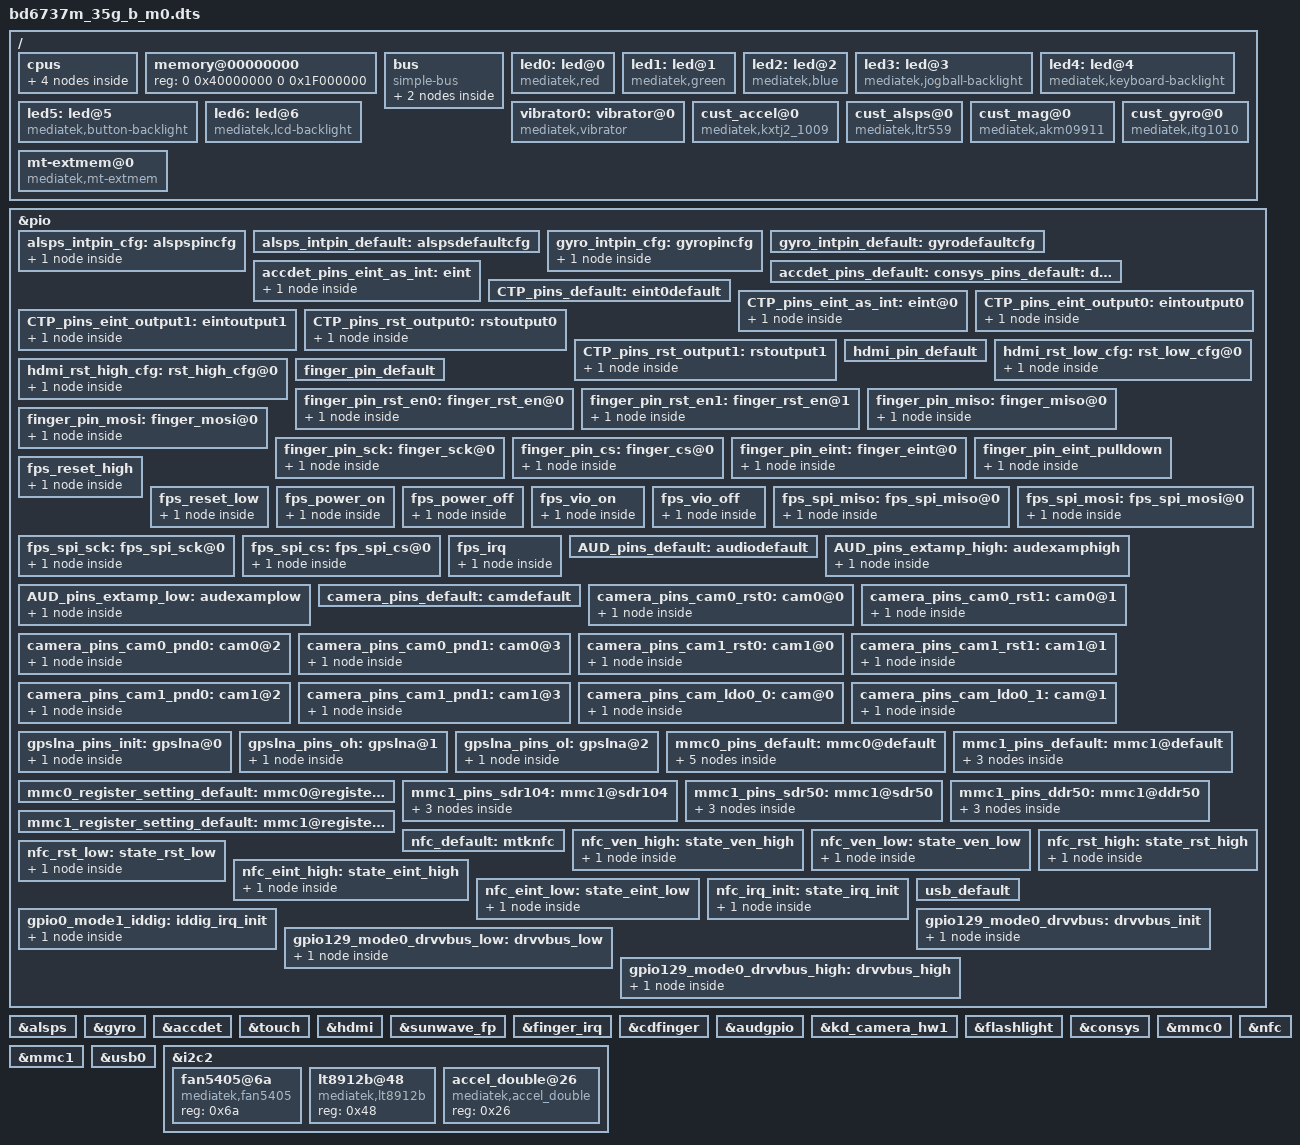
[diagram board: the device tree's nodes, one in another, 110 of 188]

/dts-v1/;

#include "mt6735m.dtsi"

/ {
	cpus {
		#address-cells = <1>;
		#size-cells = <0>;
/*		enable-method = "mediatek,mt6735-smp"; */

		cpu0: cpu@000 {
			device_type = "cpu";
			compatible = "arm,cortex-a53";
			reg = <0x000>;
			enable-method = "spin-table";
			cpu-release-addr = <0x0 0x40000200>;
			clock-frequency = <1100000000>;
		};

		cpu1: cpu@001 {
			device_type = "cpu";
			compatible = "arm,cortex-a53";
			reg = <0x001>;
			enable-method = "spin-table";
			cpu-release-addr = <0x0 0x40000200>;
			clock-frequency = <1100000000>;
		};

		cpu2: cpu@002 {
			device_type = "cpu";
			compatible = "arm,cortex-a53";
			reg = <0x002>;
			enable-method = "spin-table";
			cpu-release-addr = <0x0 0x40000200>;
			clock-frequency = <1100000000>;
		};

		cpu3: cpu@003 {
			device_type = "cpu";
			compatible = "arm,cortex-a53";
			reg = <0x003>;
			enable-method = "spin-table";
			cpu-release-addr = <0x0 0x40000200>;
			clock-frequency = <1100000000>;
		};
	};

	memory@00000000 {
		device_type = "memory";
		reg = <0 0x40000000 0 0x1F000000>;
	};

	bus {
		compatible = "simple-bus";
		#address-cells = <1>;
		#size-cells = <1>;
		ranges = <0 0 0 0xffffffff>;

		MALI@0x13040000 {
			compatible = "arm,malit720", "arm,mali-t72x", "arm,malit7xx", "arm,mali-midgard";
			reg = <0x13040000 0x4000>;
			interrupts = <0 212 0x8>, <0 211 0x8>, <0 210 0x8>;
			interrupt-names = "JOB", "MMU", "GPU";
			clock-frequency = <550000000>;
		};

		MTKFB@5e200000 {
			compatible = "mediatek,MTKFB";
			reg = <0x7F000000 0x1000000>;
		};

	};
	led0:led@0 {
		compatible = "mediatek,red";
		led_mode = <0>;
		data = <1>;
		pwm_config = <0 0 0 0 0>;
	};
	led1:led@1 {
		compatible = "mediatek,green";
		led_mode = <0>;
		data = <1>;
		pwm_config = <0 0 0 0 0>;
	};
	led2:led@2 {
		compatible = "mediatek,blue";
		led_mode = <0>;
		data = <1>;
		pwm_config = <0 0 0 0 0>;
	};
	led3:led@3 {
		compatible = "mediatek,jogball-backlight";
		led_mode = <0>;
		data = <1>;
		pwm_config = <0 0 0 0 0>;
	};
	led4:led@4 {
		compatible = "mediatek,keyboard-backlight";
		led_mode = <0>;
		data = <1>;
		pwm_config = <0 0 0 0 0>;
	};
	led5:led@5 {
		compatible = "mediatek,button-backlight";
		led_mode = <0>;
		data = <1>;
		pwm_config = <0 0 0 0 0>;
	};
	led6:led@6 {
		compatible = "mediatek,lcd-backlight";
		led_mode = <5>;
		data = <1>;
		pwm_config = <0 0 0 0 0>;
	};
	vibrator0:vibrator@0 {
		compatible = "mediatek,vibrator";
		vib_timer = <25>;
		vib_limit = <9>;
		vib_vol= <5>;
	};
 /* sensor standardization */
		cust_accel@0 {
		compatible = "mediatek,kxtj2_1009";
		i2c_num	= <2>;
		i2c_addr = <0x0e 0 0 0>;
		direction = <6>;
		power_id = <0xffff>;
		power_vol = <0>;
		firlen = <16>;
		is_batch_supported = <0>;
		};

		cust_alsps@0 {
		compatible				= "mediatek,ltr559";
		i2c_num					= <2>;
		i2c_addr				= <0x23 0 0 0>;
		polling_mode_ps			= <0>;
		polling_mode_als		= <1>;
		power_id				= <0xffff>;
		power_vol				= <0>;
/* Total has 15 level*/
	    //als_level	= <50 100 200 500 4000 8000 12000 16000 20000 24000 28000 32000 36000 40000 65535>;
/*  Total has 16 range*/
  		//als_value	= <0 15 32 80 625 1250 1875 2500 3125 3750 4375 5000 5625 6250 10240 10240>;
   als_level	= <25 50  75 100 200 500 1000 2000 5000 10000 20000 28000  36000 40000 65535>;
   als_value	= <0 300 500 700 1100 2005 3058 5005 8008 10010 12000 16000 20000 20000 20000 20000>;

		ps_threshold_high		=  <120>;
		ps_threshold_low		=  <80>;
		is_batch_supported_ps	= <0>;
		is_batch_supported_als	= <0>;
		};

		cust_mag@0 {
		compatible				= "mediatek,akm09911";
		i2c_num					= <2>;
		i2c_addr				= <0x0D 0 0 0>;
		direction				= <1>;
		power_id				= <0xffff>;
		power_vol				= <0>;
		is_batch_supported			= <0>;
		};

		cust_gyro@0 {
		compatible				= "mediatek,itg1010";
		i2c_num					= <2>;
		i2c_addr				= <0x68 0 0 0>;
		direction				= <3>;
		power_id				= <0xffff>;
		power_vol				= <0>;
		firlen					= <0>;
		is_batch_supported			= <0>;
		};

	mt-extmem@0 {
		compatible = "mediatek,mt-extmem";
	};
};
/* sensor gpio standization */
&pio {
	alsps_intpin_cfg: alspspincfg {

	    pins_cmd_dat {
			pins = <PINMUX_GPIO100__FUNC_GPIO100>;
			slew-rate = <0>;
			bias-pull-up = <00>;
		};
	};

	alsps_intpin_default: alspsdefaultcfg {

	};

	gyro_intpin_cfg: gyropincfg {

	    pins_cmd_dat {
			pins = <PINMUX_GPIO64__FUNC_GPIO64>;
			slew-rate = <0>;
			bias-pull-down = <00>;
		};
	};

	gyro_intpin_default: gyrodefaultcfg {

	};
};
&alsps {
	pinctrl-names = "pin_default", "pin_cfg";
	pinctrl-0 = <&alsps_intpin_default>;
	pinctrl-1 = <&alsps_intpin_cfg>;
	status = "okay";

};

&gyro {
	pinctrl-names = "pin_default", "pin_cfg";
	pinctrl-0 = <&gyro_intpin_default>;
	pinctrl-1 = <&gyro_intpin_cfg>;
	status = "okay";

};
/* sensor end */
&accdet {
		accdet-mic-vol = <7>;
		headset-mode-setting = <0x500 0x200 1 0x1F0 0x800 0x800 0x20>;
		accdet-plugout-debounce = <20>;
		/*1:ACC mode, 2:low cost without in bias, 6:low cost with in bias*/
		accdet-mic-mode = <1>;
		/*0--MD_MAX--UP_MAX--DW_MAX*/
		headset-three-key-threshold = <0 80 220 500>;
		/*0--MD_MAX--VOICE_MAX--UP_MAX--DW_MAX*/
		headset-four-key-threshold = <0 58 121 192 450>;
		
		pinctrl-names = "default", "state_eint_as_int";
		pinctrl-0 = <&accdet_pins_default>;
		pinctrl-1 = <&accdet_pins_eint_as_int>;
		status = "okay";
};
&pio {
	accdet_pins_default:default {
	};
	accdet_pins_eint_as_int:eint{
		pins_cmd_dat {
			pins = <PINMUX_GPIO83__FUNC_GPIO83>;
			slew-rate = <0>;
			bias-pull-up = <11>;
			output-high;
		};
	};
};
&touch {
	tpd-resolution = <720 1280>;
	use-tpd-button = <1>;
	tpd-key-num = <3>;
	tpd-key-local= <139 172 158 0>;
	tpd-key-dim-local = <100 1500 80 65 250 1500 80 65 400 1500 80 65 0 0 0 0>;
	tpd-max-touch-num = <5>;
	tpd-filter-enable = <1>;
	tpd-filter-pixel-density = <124>;
	tpd-filter-custom-prameters = <0 0 0 0 0 0 0 0 0 0 0 0>;
	tpd-filter-custom-speed = <0 0 0>;
	pinctrl-names = "default", "state_eint_as_int", "state_eint_output0", "state_eint_output1",
		"state_rst_output0", "state_rst_output1";
	pinctrl-0 = <&CTP_pins_default>;
	pinctrl-1 = <&CTP_pins_eint_as_int>;
	pinctrl-2 = <&CTP_pins_eint_output0>;
	pinctrl-3 = <&CTP_pins_eint_output1>;
	pinctrl-4 = <&CTP_pins_rst_output0>;
	pinctrl-5 = <&CTP_pins_rst_output1>;
	status = "okay";
};
&pio {
	CTP_pins_default: eint0default {
	};
	CTP_pins_eint_as_int: eint@0 {
		pins_cmd_dat {
			pins = <PINMUX_GPIO10__FUNC_GPIO10>;
			slew-rate = <0>;
			bias-pull-up = <00>;
		};
	};
	CTP_pins_eint_output0: eintoutput0 {
		pins_cmd_dat {
			pins = <PINMUX_GPIO10__FUNC_GPIO10>;
			slew-rate = <1>;
			output-low;
		};
	};
	CTP_pins_eint_output1: eintoutput1 {
		pins_cmd_dat {
			pins = <PINMUX_GPIO10__FUNC_GPIO10>;
			slew-rate = <1>;
			output-high;
		};
	};
	CTP_pins_rst_output0: rstoutput0 {
		pins_cmd_dat {
			pins = <PINMUX_GPIO62__FUNC_GPIO62>;
			slew-rate = <1>;
			output-low;
		};
	};
	CTP_pins_rst_output1: rstoutput1 {
		pins_cmd_dat {
			pins = <PINMUX_GPIO62__FUNC_GPIO62>;
			slew-rate = <1>;
			output-high;
		};
	};
};
/* TOUCH end */
/************** zhou IR_RECEIVER start **************/
//#define IR_RECEIVER_EINT_PIN_NUM    123
//#define IR_RECEIVER_EINT_PIN        PINMUX_GPIO123__FUNC_GPIO123

//&ir_irq{
//		interrupt-parent = <&eintc>;
//		interrupts = <IR_RECEIVER_EINT_PIN_NUM IRQ_TYPE_LEVEL_LOW>;
//		debounce = <IR_RECEIVER_EINT_PIN_NUM 200>;
//		status = "okay";
//	};	
	
/************** zhou hdmi start **************/	
/*
&mhl{
   pinctrl-names = "default",	
                   "i2s_dat_def","i2s_dat_cfg","i2s_ws_def","i2s_ws_cfg","i2s_ck_def","i2s_ck_cfg",
                   "rst_low_cfg", "rst_high_cfg";

   pinctrl-0 = <&hdmi_pin_default>;
   pinctrl-1 = <&hdmi_i2s_dat_def>;
   pinctrl-2 = <&hdmi_i2s_dat_cfg>;
   pinctrl-3 = <&hdmi_i2s_ws_def>;
   pinctrl-4 = <&hdmi_i2s_ws_cfg>;   
   pinctrl-5 = <&hdmi_i2s_ck_def>;
   pinctrl-6 = <&hdmi_i2s_ck_cfg>;   
   pinctrl-7 = <&hdmi_rst_low_cfg>;
   pinctrl-8 = <&hdmi_rst_high_cfg>;      
  	status = "okay";  
};

&pio {
	hdmi_pin_default:hdmi_pin_default{
	 
  };
	hdmi_i2s_dat_def:i2s_dat_def@0{
		  pins_cmd_dat {
			pins = <PINMUX_GPIO78__FUNC_GPIO78>;
			slew-rate = <0>;
			bias-pull-down = <11>;
		};
	 };  
	hdmi_i2s_dat_cfg:i2s_dat_cfg@0{
		  pins_cmd_dat {
			pins = <PINMUX_GPIO78__FUNC_I2S3_DO>;
			slew-rate = <1>;
		};
	 };    
	hdmi_i2s_ws_def:i2s_ws_def@0{
		  pins_cmd_dat {
			pins = <PINMUX_GPIO79__FUNC_GPIO79>;
			slew-rate = <0>;
			bias-pull-down = <11>;
		};
	 };  
	hdmi_i2s_ws_cfg:i2s_ws_cfg@0{
		  pins_cmd_dat {
			pins = <PINMUX_GPIO79__FUNC_I2S3_LRCK>;
			slew-rate = <1>;
		};
	 };
	hdmi_i2s_ck_def:i2s_ck_def@0{
		  pins_cmd_dat {
			pins = <PINMUX_GPIO80__FUNC_GPIO80>;
			slew-rate = <0>;
			bias-pull-down = <11>;
		};
	 };  
	hdmi_i2s_ck_cfg:i2s_ck_cfg@0{
		  pins_cmd_dat {
			pins = <PINMUX_GPIO80__FUNC_I2S3_BCK>;
			slew-rate = <1>;
		};
	 };	   
	 hdmi_rst_low_cfg:rst_low_cfg@0{
	     pins_cmd_dat {
		   pins = <PINMUX_GPIO120__FUNC_GPIO120>;
		   slew-rate=<1>;
		   output-low;
		 };
	 };
	 hdmi_rst_high_cfg:rst_high_cfg@0{
	     pins_cmd_dat {
		   pins = <PINMUX_GPIO120__FUNC_GPIO120>;
		   slew-rate=<1>;
		   output-high;
		 };
	 };
};
*/

&hdmi{
   pinctrl-names = "default", "rst_low_cfg", "rst_high_cfg";

   pinctrl-0 = <&hdmi_pin_default>;  
   pinctrl-1 = <&hdmi_rst_low_cfg>;
   pinctrl-2 = <&hdmi_rst_high_cfg>;      
  	status = "okay";  
};

&pio {
	hdmi_pin_default:hdmi_pin_default{
	 
  };   
	 hdmi_rst_low_cfg:rst_low_cfg@0{
	     pins_cmd_dat {
		   pins = <PINMUX_GPIO120__FUNC_GPIO120>;
		   slew-rate=<1>;
		   output-low;
		 };
	 };
	 hdmi_rst_high_cfg:rst_high_cfg@0{
	     pins_cmd_dat {
		   pins = <PINMUX_GPIO120__FUNC_GPIO120>;
		   slew-rate=<1>;
		   output-high;
		 };
	 };
};

/************** zhou FINGERPRINT start **************/
/*SUNWAVE FINGERPRINT DTS begin*/
#define SUNWAVE_FINGER_EINT_PIN_NUM    125
#define SUNWAVE_FINGER_EINT_PIN        PINMUX_GPIO125__FUNC_GPIO125
#define SUNWAVE_FINGER_RST_PIN         PINMUX_GPIO127__FUNC_GPIO127

&sunwave_fp{
    pinctrl-names = "default","finger_rst_en0","finger_rst_en1","finger_miso","finger_mosi","finger_sck","finger_cs","finger_eint","finger_eint_pulldown"; 

    pinctrl-0 = <&finger_pin_default>;
    pinctrl-1 = <&finger_pin_rst_en0>;
    pinctrl-2 = <&finger_pin_rst_en1>;
    pinctrl-3 = <&finger_pin_miso>;
    pinctrl-4 = <&finger_pin_mosi>;
    pinctrl-5 = <&finger_pin_sck>;
    pinctrl-6 = <&finger_pin_cs>;
    pinctrl-7 = <&finger_pin_eint>;
    pinctrl-8 = <&finger_pin_eint_pulldown>;    
    //fingerprint,touch-int-gpio = <&pio MICROARRAY_FINGER_EINT_PIN_NUM 0>;

};

&pio {
	finger_pin_default:finger_pin_default{
	 
	 };
	 finger_pin_rst_en0:finger_rst_en@0{
	     pins_cmd_dat {
		   pins = <SUNWAVE_FINGER_RST_PIN>;
		   slew-rate=<1>;
		   output-low;
		 };
	 };
	 finger_pin_rst_en1:finger_rst_en@1{
	     pins_cmd_dat {
		   pins = <SUNWAVE_FINGER_RST_PIN>;
		   slew-rate=<1>;
		   output-high;
		 };
	 };

	finger_pin_miso:finger_miso@0{
	     pins_cmd_dat {
		  	pins = <PINMUX_GPIO67__FUNC_SPI_MIA>;
			slew-rate = <0>;
			//bias-pull-up = <11>;
            output-low;
            //input-schmitt-enable = <0>;
		 };
	 };
	finger_pin_mosi:finger_mosi@0{
	     pins_cmd_dat {
		  	pins = <PINMUX_GPIO68__FUNC_SPI_MOA>; 
            slew-rate = <1>;
			//bias-pull-up = <11>;
			//input-schmitt-enable = <0>;
            output-low;
		 };
	 };
	finger_pin_sck:finger_sck@0{
	     pins_cmd_dat {
		    pins = <PINMUX_GPIO66__FUNC_SPI_CKA>;
            slew-rate = <1>;
			//bias-pull-up = <11>;
			//input-schmitt-enable = <0>;
            output-low;
		 };
	 };
	finger_pin_cs:finger_cs@0{
	     pins_cmd_dat {
		        pins = <PINMUX_GPIO65__FUNC_SPI_CSA>;
                slew-rate = <1>;
		  // 	bias-pull-up = <11>;
			//input-schmitt-enable = <0>;
                output-low;
		 };
	 };

	finger_pin_eint:finger_eint@0{
	     pins_cmd_dat {
		   pins = <SUNWAVE_FINGER_EINT_PIN>;
		   slew-rate=<0>;
		   bias-pull-up = <00>;

		 };
	 };

  finger_pin_eint_pulldown:finger_pin_eint_pulldown{
	     pins_cmd_dat {
		   pins = <SUNWAVE_FINGER_EINT_PIN>;
		   slew-rate=<0>;
		   bias-pull-down = <00>;

		 };
	 }; 
	 
};

&finger_irq{
		interrupt-parent = <&eintc>;
		interrupts = <SUNWAVE_FINGER_EINT_PIN_NUM IRQ_TYPE_EDGE_FALLING>;
		debounce = <SUNWAVE_FINGER_EINT_PIN_NUM 0>;
		status = "okay";
	};
	
/*FEGE FINGERPRINT DTS begin*/

&cdfinger{
		  reg = <0>;
		  interrupt-parent = <&eintc>;
		  interrupts = <125 IRQ_TYPE_EDGE_RISING>;
		  debounce = <125 0>;  
		  vdd_ldo_enable = <0>;
		  vio_ldo_enable = <0>;
		  config_spi_pin = <1>;
		  spi-max-frequency = <8000000>;	
		  
	  pinctrl-names = "fingerprint_reset_high",
      "fingerprint_reset_low",
			"fingerprint_power_high",
			"fingerprint_power_low",
			"fingerprint_vio_high",
			"fingerprint_vio_low",
			"fingerprint_spi_miso",
			"fingerprint_spi_mosi",
			"fingerprint_spi_sck",
			"fingerprint_spi_cs",
			"fingerprint_irq";

		pinctrl-0 = <&fps_reset_high>;
		pinctrl-1 = <&fps_reset_low>;
		pinctrl-2 = <&fps_power_on>;
		pinctrl-3 = <&fps_power_off>;
		pinctrl-4 = <&fps_vio_on>;
		pinctrl-5 = <&fps_vio_off>;
		pinctrl-6 = <&fps_spi_miso>;
		pinctrl-7 = <&fps_spi_mosi>;
		pinctrl-8 = <&fps_spi_sck>;
		pinctrl-9 = <&fps_spi_cs>;
		pinctrl-10 = <&fps_irq>;
		status = "okay";
	};
	
&pio {
	fps_reset_high: fps_reset_high {
		pins_cmd_dat {
			pins = <PINMUX_GPIO127__FUNC_GPIO127>;
			slew-rate = <1>;
			bias-disable;
			output-high;
		};
	};
	fps_reset_low: fps_reset_low {
		pins_cmd_dat {
			pins = <PINMUX_GPIO127__FUNC_GPIO127>;
			slew-rate = <1>;
			bias-disable;
			output-low;
		};
	};
	fps_power_on: fps_power_on {
		pins_cmd_dat {
			pins = <PINMUX_GPIO64__FUNC_GPIO64>;
			slew-rate = <1>;
			bias-disable;
			output-high;
		};
	};
	fps_power_off: fps_power_off {
		pins_cmd_dat {
			pins = <PINMUX_GPIO64__FUNC_GPIO64>;
			slew-rate = <1>;
			bias-disable;
			output-low;
		};
	};
	fps_vio_on: fps_vio_on {
		pins_cmd_dat {
			pins = <PINMUX_GPIO64__FUNC_GPIO64>;
			slew-rate = <1>;
			bias-disable;
			output-high;
		};
	};
	fps_vio_off: fps_vio_off {
		pins_cmd_dat {
			pins = <PINMUX_GPIO64__FUNC_GPIO64>;
			slew-rate = <1>;
			bias-disable;
			output-low;
		};
	};
	fps_spi_miso:fps_spi_miso@0{
		pins_cmd_dat {
			pins = <PINMUX_GPIO67__FUNC_SPI_MIA>;
			slew-rate = <0>;
			bias-pull-up = <11>;
			output-low;
		};
	};
	fps_spi_mosi:fps_spi_mosi@0{
		pins_cmd_dat {
			pins = <PINMUX_GPIO68__FUNC_SPI_MOA>;
			slew-rate = <1>;
			bias-pull-up = <11>;
			output-low;
		};
	};
	fps_spi_sck:fps_spi_sck@0{
		pins_cmd_dat {
			pins = <PINMUX_GPIO66__FUNC_SPI_CKA>;
			slew-rate = <1>;
			bias-pull-up = <11>;
			output-low;
		};
	};
	fps_spi_cs:fps_spi_cs@0{
		pins_cmd_dat {
			pins = <PINMUX_GPIO65__FUNC_SPI_CSA>;
			slew-rate = <1>;
			bias-pull-up = <11>;
			output-low;
		};
	};
	fps_irq: fps_irq {
		pins_cmd_dat {
			pins = <PINMUX_GPIO125__FUNC_GPIO125>;
			slew-rate = <0>;
			bias-disable;
			output-low;
		};
	};
};

/*finger end, orangepi*/

/* AUDIO GPIO standardization */
&audgpio {
	pinctrl-names = "default", "extamp-pullhigh", "extamp-pulllow";
	pinctrl-0 = <&AUD_pins_default>;
  pinctrl-1 = <&AUD_pins_extamp_high>;
	pinctrl-2 = <&AUD_pins_extamp_low>;	
	status = "okay";
};
&pio {
	AUD_pins_default: audiodefault {
	};
	
	AUD_pins_extamp_high: audexamphigh {
		pins_cmd_dat {
			pins = <PINMUX_GPIO94__FUNC_GPIO94>;  
			slew-rate = <1>;
			output-high;
		};
	};
	AUD_pins_extamp_low: audexamplow {
		pins_cmd_dat {
			pins = <PINMUX_GPIO94__FUNC_GPIO94>;
			slew-rate = <1>;
			output-low;
		};
	};
};
/* AUDIO end */

/* CAMERA GPIO standardization */
&pio {
	camera_pins_default: camdefault {
	};
	camera_pins_cam0_rst0: cam0@0 {
		pins_cmd_dat {
			pins = <PINMUX_GPIO44__FUNC_GPIO44>;/*GPIO_CAMERA_CMRST_PIN*/
			slew-rate = <1>; /*direction 0:in, 1:out*/
			output-low;/*direction out used only. output_low or high*/
		};
	};
	camera_pins_cam0_rst1: cam0@1 {
		pins_cmd_dat {
			pins = <PINMUX_GPIO44__FUNC_GPIO44>;/*GPIO_CAMERA_CMRST_PIN*/
			slew-rate = <1>;
			output-high;
		};
	};
	camera_pins_cam0_pnd0: cam0@2 {
		pins_cmd_dat {
			pins = <PINMUX_GPIO7__FUNC_GPIO7>;/*GPIO_CAMERA_CMPDN_PIN*/
			slew-rate = <1>;
			output-low;
		};
	};
	camera_pins_cam0_pnd1: cam0@3 {
		pins_cmd_dat {
			pins = <PINMUX_GPIO7__FUNC_GPIO7>;/*GPIO_CAMERA_CMPDN_PIN*/
			slew-rate = <1>;
			output-high;
		};
	};
	camera_pins_cam1_rst0: cam1@0 {
		pins_cmd_dat {
			pins = <PINMUX_GPIO11__FUNC_GPIO11>;/*GPIO_CAMERA_CMRST1_PIN*/
			slew-rate = <1>; /*direction 0:in, 1:out*/
			output-low;/*direction out used only. output_low or high*/
		};
	};
	camera_pins_cam1_rst1: cam1@1 {
		pins_cmd_dat {
			pins = <PINMUX_GPIO11__FUNC_GPIO11>;/*GPIO_CAMERA_CMRST1_PIN*/
			slew-rate = <1>;
			output-high;
		};
	};
	camera_pins_cam1_pnd0: cam1@2 {
		pins_cmd_dat {
			pins = <PINMUX_GPIO12__FUNC_GPIO12>;/*GPIO_CAMERA_CMPDN1_PIN*/
			slew-rate = <1>;
			output-low;
		};
	};
	camera_pins_cam1_pnd1: cam1@3 {
		pins_cmd_dat {
			pins = <PINMUX_GPIO12__FUNC_GPIO12>;/*GPIO_CAMERA_CMPDN1_PIN*/
			slew-rate = <1>;
			output-high;
		};
	};
	camera_pins_cam_ldo0_0: cam@0 {
		pins_cmd_dat {
			pins = <PINMUX_GPIO64__FUNC_GPIO64>;
			slew-rate = <1>;
			output-low;
		};
	};
	camera_pins_cam_ldo0_1: cam@1 {
		pins_cmd_dat {
			pins = <PINMUX_GPIO64__FUNC_GPIO64>;
			slew-rate = <1>;
			output-high;
		};
	};	
	
};

&kd_camera_hw1 {
	pinctrl-names = "default", "cam0_rst0", "cam0_rst1", "cam0_pnd0", "cam0_pnd1",
	"cam1_rst0", "cam1_rst1", "cam1_pnd0", "cam1_pnd1",  "cam_ldo0_0", "cam_ldo0_1";
	pinctrl-0 = <&camera_pins_default>;
	pinctrl-1 = <&camera_pins_cam0_rst0>;
	pinctrl-2 = <&camera_pins_cam0_rst1>;
	pinctrl-3 = <&camera_pins_cam0_pnd0>;
	pinctrl-4 = <&camera_pins_cam0_pnd1>;
	pinctrl-5 = <&camera_pins_cam1_rst0>;
	pinctrl-6 = <&camera_pins_cam1_rst1>;
	pinctrl-7 = <&camera_pins_cam1_pnd0>;
	pinctrl-8 = <&camera_pins_cam1_pnd1>;
	pinctrl-9 = <&camera_pins_cam_ldo0_0>;
	pinctrl-10 = <&camera_pins_cam_ldo0_1>;
	status = "okay";			

};
/* CAMERA GPIO end */

/* flashlight gpio standardization. orangepi add*/
&flashlight{    
  	flash_en_gpio = <&pio 43 0>;
  	flash_mo_gpio = <&pio 42 0>;
  	sub_flash_en_gpio = <&pio 64 0>;  	  	
		status = "okay";
	};
/* FLASHLISHT GPIO end */

/* CONSYS GPIO standardization */
&pio {
	consys_pins_default: default {

	};

	gpslna_pins_init: gpslna@0 {

	    pins_cmd_dat {
			pins = <PINMUX_GPIO102__FUNC_GPIO102>;
			slew-rate = <0>;
			bias-disable;
			output-low;
		};
	};

	gpslna_pins_oh: gpslna@1 {

	    pins_cmd_dat {
			pins = <PINMUX_GPIO102__FUNC_GPIO102>;
			slew-rate = <1>;
			output-high;
		};
	};

	gpslna_pins_ol: gpslna@2 {

	    pins_cmd_dat {
			pins = <PINMUX_GPIO102__FUNC_GPIO102>;
			slew-rate = <1>;
			output-low;
		};
	};

};

&consys {
	pinctrl-names = "default", "gps_lna_state_init", "gps_lna_state_oh", "gps_lna_state_ol";
	pinctrl-0 = <&consys_pins_default>;
	pinctrl-1 = <&gpslna_pins_init>;
	pinctrl-2 = <&gpslna_pins_oh>;
	pinctrl-3 = <&gpslna_pins_ol>;
	status = "okay";

};
/* CONSYS end */

/* mmc start */
&mmc0 {
		clk_src = /bits/ 8 <MSDC50_CLKSRC_400MHZ>;
		bus-width = <8>;
		max-frequency = <200000000>;
		cap-mmc-highspeed;
		msdc-sys-suspend;
		mmc-ddr-1_8v;
		mmc-hs200-1_8v;
		mmc-hs400-1_8v;
		non-removable;
		pinctl = <&mmc0_pins_default>;
		register_setting = <&mmc0_register_setting_default>;
		host_function = /bits/ 8 <MSDC_EMMC>;
		bootable;
		status = "okay";
};

&mmc1 {
		clk_src = /bits/ 8 <MSDC30_CLKSRC_200MHZ>;
		bus-width = <4>;
		max-frequency = <200000000>;
		msdc-sys-suspend;
		cap-sd-highspeed;
		sd-uhs-sdr12;
		sd-uhs-sdr25;
		sd-uhs-sdr50;
		sd-uhs-sdr104;
		sd-uhs-ddr50;
		pinctl = <&mmc1_pins_default>;
		pinctl_sdr104 = <&mmc1_pins_sdr104>;
		pinctl_sdr50 = <&mmc1_pins_sdr50>;
		pinctl_ddr50 = <&mmc1_pins_ddr50>;
		register_setting = <&mmc1_register_setting_default>;
		host_function = /bits/ 8 <MSDC_SD>;
		cd_level = /bits/ 8 <MSDC_CD_LOW>;
		cd-gpios = <&pio 1 0>;
		status = "okay";
};

&pio {
	mmc0_pins_default: mmc0@default {
			pins_cmd {
				drive-strength = /bits/ 8 <2>;
			};
			pins_dat {
				drive-strength = /bits/ 8 <2>;
			};
			pins_clk {
				drive-strength = /bits/ 8 <2>;
			};
			pins_rst {
				drive-strength = /bits/ 8 <2>;
			};
			pins_ds {
				drive-strength = /bits/ 8 <2>;
			};
	};

	mmc0_register_setting_default: mmc0@register_default {
		dat0rddly      = /bits/ 8 <0>;
		dat1rddly      = /bits/ 8 <0>;
		dat2rddly      = /bits/ 8 <0>;
		dat3rddly      = /bits/ 8 <0>;
		dat4rddly      = /bits/ 8 <0>;
		dat5rddly      = /bits/ 8 <0>;
		dat6rddly      = /bits/ 8 <0>;
		dat7rddly      = /bits/ 8 <0>;
		datwrddly      = /bits/ 8 <0>;
		cmdrrddly      = /bits/ 8 <0>;
		cmdrddly       = /bits/ 8 <0>;
		cmd_edge = /bits/ 8 <MSDC_SMPL_FALLING>;
		rdata_edge = /bits/ 8 <MSDC_SMPL_FALLING>;
		wdata_edge = /bits/ 8 <MSDC_SMPL_FALLING>;

		ett-hs200-cells = <12>;
		ett-hs200-default = <OFFSET_MSDC_PATCH_BIT0	MSDC_PB0_INT_DAT_LATCH_CK_SEL 0x0
			OFFSET_MSDC_PATCH_BIT0	MSDC_PB0_CKGEN_MSDC_DLY_SEL   0x0
			OFFSET_MSDC_PATCH_BIT1	MSDC_PB1_CMD_RSP_TA_CNTR      0x1
			OFFSET_MSDC_IOCON		MSDC_IOCON_RSPL               0x0
			OFFSET_MSDC_PAD_TUNE0	MSDC_PAD_TUNE0_CMDRDLY        0x7
			OFFSET_MSDC_PAD_TUNE0	MSDC_PAD_TUNE0_CMDRRDLY       0xb
			OFFSET_MSDC_PATCH_BIT1		MSDC_PB1_WRDAT_CRCS_TA_CNTR   0x1
			OFFSET_MSDC_PAD_TUNE0	MSDC_PAD_TUNE0_DATWRDLY       0xb
			OFFSET_MSDC_IOCON			MSDC_IOCON_W_D0SPL            0x0
			OFFSET_MSDC_DAT_RDDLY0		MSDC_DAT_RDDLY0_D0            0x7
			OFFSET_MSDC_PAD_TUNE0	MSDC_PAD_TUNE0_DATRRDLY       0x9
			OFFSET_MSDC_IOCON		MSDC_IOCON_R_D_SMPL           0x0>;

		ett-hs400-cells = <8>;
		ett-hs400-default = <OFFSET_MSDC_PATCH_BIT0	MSDC_PB0_INT_DAT_LATCH_CK_SEL	0x0
			OFFSET_MSDC_PATCH_BIT0		MSDC_PB0_CKGEN_MSDC_DLY_SEL		0x0
			OFFSET_EMMC50_PAD_DS_TUNE	MSDC_EMMC50_PAD_DS_TUNE_DLY1	0x2
			OFFSET_EMMC50_PAD_DS_TUNE	MSDC_EMMC50_PAD_DS_TUNE_DLY3	0x10
			OFFSET_MSDC_PATCH_BIT1			MSDC_PB1_CMD_RSP_TA_CNTR	0x1
			OFFSET_MSDC_IOCON		MSDC_IOCON_RSPL				0x0
			OFFSET_MSDC_PAD_TUNE0			MSDC_PAD_TUNE0_CMDRDLY		0x6
			OFFSET_MSDC_PAD_TUNE0		MSDC_PAD_TUNE0_CMDRRDLY		0x6>;
	};

	mmc1_pins_default: mmc1@default {
			pins_cmd {
				drive-strength = /bits/ 8 <3>;
			};
			pins_dat {
				drive-strength = /bits/ 8 <3>;
			};
			pins_clk {
				drive-strength = /bits/ 8 <3>;
			};
	};

	mmc1_pins_sdr104: mmc1@sdr104 {
			pins_cmd {
				drive-strength = /bits/ 8 <2>;
			};
			pins_dat {
				drive-strength = /bits/ 8 <2>;
			};
			pins_clk {
				drive-strength = /bits/ 8 <3>;
			};
	};

	mmc1_pins_sdr50: mmc1@sdr50 {
			pins_cmd {
				drive-strength = /bits/ 8 <2>;
			};
			pins_dat {
				drive-strength = /bits/ 8 <2>;
			};
			pins_clk {
				drive-strength = /bits/ 8 <3>;
			};
	};

	mmc1_pins_ddr50: mmc1@ddr50 {
			pins_cmd {
				drive-strength = /bits/ 8 <2>;
			};
			pins_dat {
				drive-strength = /bits/ 8 <2>;
			};
			pins_clk {
				drive-strength = /bits/ 8 <3>;
			};
	};

	mmc1_register_setting_default: mmc1@register_default {
				dat0rddly      = /bits/ 8 <0>;
				dat1rddly      = /bits/ 8 <0>;
				dat2rddly      = /bits/ 8 <0>;
				dat3rddly      = /bits/ 8 <0>;
				datwrddly      = /bits/ 8 <0>;
				cmdrrddly      = /bits/ 8 <0>;
				cmdrddly       = /bits/ 8 <0>;
				cmd_edge = /bits/ 8 <MSDC_SMPL_FALLING>;
				rdata_edge = /bits/ 8 <MSDC_SMPL_FALLING>;
				wdata_edge = /bits/ 8 <MSDC_SMPL_FALLING>;
	};
};
/* mmc end */

/* NFC GPIO standardization */
&pio {
	nfc_default: mtknfc {

	};

	nfc_ven_high: state_ven_high {
		pins_cmd_dat {
			pins = <PINMUX_GPIO4__FUNC_GPIO4>;
			slew-rate = <1>;
			output-high;
		};
	};

	nfc_ven_low: state_ven_low {
		pins_cmd_dat {
			pins = <PINMUX_GPIO4__FUNC_GPIO4>;
			slew-rate = <1>;
			output-low;
		};
	};

	nfc_rst_high: state_rst_high {
		pins_cmd_dat {
			pins = <PINMUX_GPIO3__FUNC_GPIO3>;
			slew-rate = <1>;
			output-high;
		};
	};

	nfc_rst_low: state_rst_low {
		pins_cmd_dat {
			pins = <PINMUX_GPIO3__FUNC_GPIO3>;
			slew-rate = <1>;
			output-low;
		};
	};

	nfc_eint_high: state_eint_high {
		pins_cmd_dat {
			pins = <PINMUX_GPIO1__FUNC_GPIO1>;
			slew-rate = <1>;
			output-high;
		};
	};

	nfc_eint_low: state_eint_low {
		pins_cmd_dat {
			pins = <PINMUX_GPIO1__FUNC_GPIO1>;
			slew-rate = <1>;
			output-low;
		};
	};

	nfc_irq_init: state_irq_init {
		pins_cmd_dat {
		pins = <PINMUX_GPIO64__FUNC_GPIO64>;
			slew-rate = <0>;
			bias-pull-down = <00>;
		};
	};
};

&nfc {
	pinctrl-names = "mtknfc", "ven_high", "ven_low", "rst_high", "rst_low", "eint_high", "eint_low", "irq_init";
	pinctrl-0 = <&nfc_default>;
	pinctrl-1 = <&nfc_ven_high>;
	pinctrl-2 = <&nfc_ven_low>;
	pinctrl-3 = <&nfc_rst_high>;
	pinctrl-4 = <&nfc_rst_low>;
	pinctrl-5 = <&nfc_eint_high>;
	pinctrl-6 = <&nfc_eint_low>;
	pinctrl-7 = <&nfc_irq_init>;
	status = "okay";
};
/* NFC end */

/* USB GPIO Kernal Standardization start */
&pio {
	usb_default: usb_default {
	};

	gpio0_mode1_iddig: iddig_irq_init {
		pins_cmd_dat {
			pins = <PINMUX_GPIO0__FUNC_IDDIG>;
			slew-rate = <0>;
			bias-pull-up = <00>;
		};
	};

	gpio129_mode0_drvvbus: drvvbus_init {
		pins_cmd_dat {
			pins = <PINMUX_GPIO129__FUNC_GPIO129>;
			slew-rate = <1>;
			bias-pull-down = <00>;
		};
	};

	gpio129_mode0_drvvbus_low: drvvbus_low {
		pins_cmd_dat {
			pins = <PINMUX_GPIO129__FUNC_GPIO129>;
			slew-rate = <1>;
			output-low;
			bias-pull-down = <00>;
		};
	};

	gpio129_mode0_drvvbus_high: drvvbus_high {
		pins_cmd_dat {
			pins = <PINMUX_GPIO129__FUNC_GPIO129>;
			slew-rate = <1>;
			output-high;
			bias-pull-down = <00>;
		};
	};
};

&usb0 {
	iddig_gpio = <0 1>;
	pinctrl-names = "usb_default", "iddig_irq_init", "drvvbus_init", "drvvbus_low", "drvvbus_high";
	pinctrl-0 = <&usb_default>;
	pinctrl-1 = <&gpio0_mode1_iddig>;
	pinctrl-2 = <&gpio129_mode0_drvvbus>;
	pinctrl-3 = <&gpio129_mode0_drvvbus_low>;
	pinctrl-4 = <&gpio129_mode0_drvvbus_high>;
	status = "okay";
};
/* USB GPIO Kernal Standardization end */

//quick charge
&i2c2{
	fan5405@6a {
		compatible = "mediatek,fan5405";
		reg = <0x6a>;
	};
};
//orangepi hdmi
&i2c2{
	lt8912b@48 {
		compatible = "mediatek,lt8912b";
		reg = <0x48>;
	};
};
//accel
&i2c2{
  accel_double@26 {
		compatible = "mediatek,accel_double";  
		reg = <0x26>;
	};
};
/* add by zhou for sensor compatible end*/
